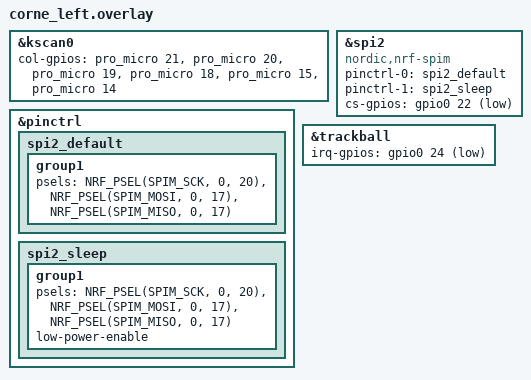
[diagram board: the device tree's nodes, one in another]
/*
 * Copyright (c) 2020 Pete Johanson
 *
 * SPDX-License-Identifier: MIT
 */

#include "corne.dtsi"

&kscan0 {
    col-gpios
        = <&pro_micro 21 GPIO_ACTIVE_HIGH>
        , <&pro_micro 20 GPIO_ACTIVE_HIGH>
        , <&pro_micro 19 GPIO_ACTIVE_HIGH>
        , <&pro_micro 18 GPIO_ACTIVE_HIGH>
        , <&pro_micro 15 GPIO_ACTIVE_HIGH>
        , <&pro_micro 14 GPIO_ACTIVE_HIGH>
        ;
};


&pinctrl {
    spi2_default: spi2_default {
        group1 {
            psels = <NRF_PSEL(SPIM_SCK, 0, 20)>,
                <NRF_PSEL(SPIM_MOSI, 0, 17)>,
                <NRF_PSEL(SPIM_MISO, 0, 17)>;
        };
    };
    spi2_sleep: spi2_sleep {
        group1 {
            psels = <NRF_PSEL(SPIM_SCK, 0, 20)>,
                <NRF_PSEL(SPIM_MOSI, 0, 17)>,
                <NRF_PSEL(SPIM_MISO, 0, 17)>;
            low-power-enable;
        };
    };
};

&spi2 {
    compatible = "nordic,nrf-spim";
    pinctrl-0 = <&spi2_default>;
    pinctrl-1 = <&spi2_sleep>;
    pinctrl-names = "default", "sleep";
    cs-gpios = <&gpio0 22 GPIO_ACTIVE_LOW>;
};


/* Enable spi2 bus and the trackball, and define their pins */
/*
&spi2 {
  status = "okay";
  sck-pin = <17>;
  mosi-pin = <20>;
  miso-pin = <20>; // same as mosi (3-wire spi)
  cs-gpios = <&gpio0 22 GPIO_ACTIVE_LOW>;
};
*/


&trackball {
  status = "okay";
  irq-gpios = <&gpio0 24 (GPIO_ACTIVE_LOW | GPIO_PULL_UP)>;
};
